VERSION "914 EV telemetry -- generated by generate_914_dbc.py, do not hand-edit"

NS_ :

BS_:

BU_: VCU INVERTER CHARGER LOGGER

BO_ 2667577344 BmsStatus: 8 VCU
 SG_ Flt_CellOverVoltage_Latched : 0|1@1+ (1,0) [0|1] "" LOGGER
 SG_ Flt_CellUnderVoltage_Latched : 1|1@1+ (1,0) [0|1] "" LOGGER
 SG_ Flt_OverTemp_Latched : 2|1@1+ (1,0) [0|1] "" LOGGER
 SG_ Flt_StringImbalance_Latched : 3|1@1+ (1,0) [0|1] "" LOGGER
 SG_ Flt_Pec_Latched : 4|1@1+ (1,0) [0|1] "" LOGGER
 SG_ Flt_CellOverVoltage_Now : 8|1@1+ (1,0) [0|1] "" LOGGER
 SG_ Flt_CellUnderVoltage_Now : 9|1@1+ (1,0) [0|1] "" LOGGER
 SG_ Flt_OverTemp_Now : 10|1@1+ (1,0) [0|1] "" LOGGER
 SG_ Flt_StringImbalance_Now : 11|1@1+ (1,0) [0|1] "" LOGGER
 SG_ Flt_Pec_Now : 12|1@1+ (1,0) [0|1] "" LOGGER
 SG_ Sts_Discharging : 16|1@1+ (1,0) [0|1] "" LOGGER
 SG_ Sts_ChargeSwitch : 17|1@1+ (1,0) [0|1] "" LOGGER
 SG_ Sts_ChargeEnable : 18|1@1+ (1,0) [0|1] "" LOGGER
 SG_ Sts_Contactors : 19|1@1+ (1,0) [0|1] "" LOGGER
 SG_ Sts_Balancing : 20|1@1+ (1,0) [0|1] "" LOGGER
 SG_ Sts_SocReserve : 21|1@1+ (1,0) [0|1] "" LOGGER
 SG_ Sts_VoltageCheckOk : 22|1@1+ (1,0) [0|1] "" LOGGER
 SG_ Sts_StringCheckOk : 23|1@1+ (1,0) [0|1] "" LOGGER
 SG_ Ioexp_G : 24|1@1+ (1,0) [0|1] "" LOGGER
 SG_ Ioexp_LowFuel : 27|1@1+ (1,0) [0|1] "" LOGGER
 SG_ Ioexp_Egr : 28|1@1+ (1,0) [0|1] "" LOGGER
 SG_ Ioexp_BmsErr : 31|1@1+ (1,0) [0|1] "" LOGGER
 SG_ IoexpMask : 32|8@1+ (1,0) [0|255] "" LOGGER
 SG_ ErrCount : 40|16@1+ (1,0) [0|65535] "" LOGGER
 SG_ Gpi_Pin08 : 56|1@1+ (1,0) [0|1] "" LOGGER
 SG_ Gpi_Pin09 : 57|1@1+ (1,0) [0|1] "" LOGGER
 SG_ Gpi_Pin10 : 58|1@1+ (1,0) [0|1] "" LOGGER
 SG_ Gpi_Knob1Sw : 59|1@1+ (1,0) [0|1] "" LOGGER
 SG_ Gpi_Knob2Sw : 60|1@1+ (1,0) [0|1] "" LOGGER
 SG_ Gpi_Pin13 : 61|1@1+ (1,0) [0|1] "" LOGGER
 SG_ Gpi_Pin14 : 62|1@1+ (1,0) [0|1] "" LOGGER
 SG_ Gpi_Pin15 : 63|1@1+ (1,0) [0|1] "" LOGGER

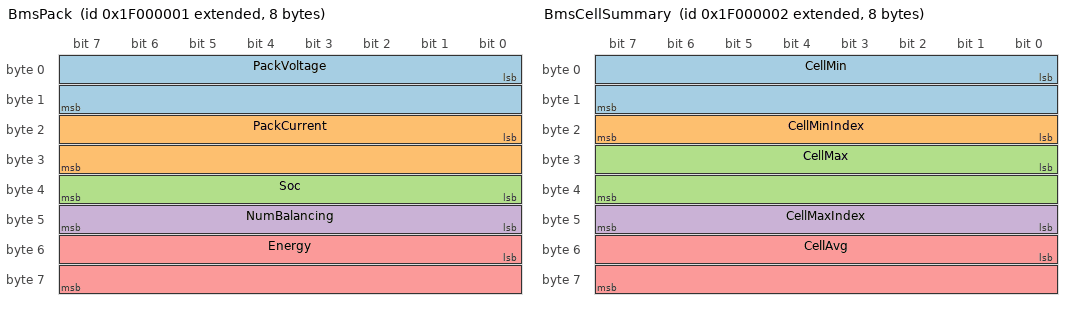
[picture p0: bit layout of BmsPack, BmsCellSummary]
BO_ 2667577345 BmsPack: 8 VCU
 SG_ PackVoltage : 0|16@1+ (0.1,0) [0|6553.5] "V" LOGGER
 SG_ PackCurrent : 16|16@1- (0.01,0) [-327.68|327.67] "A" LOGGER
 SG_ Soc : 32|8@1+ (1,0) [0|100] "%" LOGGER
 SG_ NumBalancing : 40|8@1+ (1,0) [0|168] "" LOGGER
 SG_ Energy : 48|16@1+ (0.01,0) [0|655.35] "kWh" LOGGER

BO_ 2667577346 BmsCellSummary: 8 VCU
 SG_ CellMin : 0|16@1+ (1,0) [0|65535] "mV" LOGGER
 SG_ CellMinIndex : 16|8@1+ (1,0) [0|167] "" LOGGER
 SG_ CellMax : 24|16@1+ (1,0) [0|65535] "mV" LOGGER
 SG_ CellMaxIndex : 40|8@1+ (1,0) [0|167] "" LOGGER
 SG_ CellAvg : 48|16@1+ (1,0) [0|65535] "mV" LOGGER

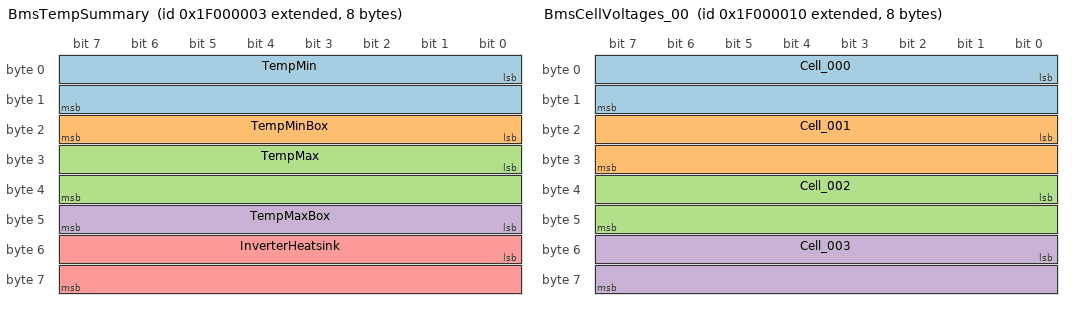
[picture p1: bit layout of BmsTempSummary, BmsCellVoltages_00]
BO_ 2667577347 BmsTempSummary: 8 VCU
 SG_ TempMin : 0|16@1- (0.1,0) [-3276.8|3276.7] "degC" LOGGER
 SG_ TempMinBox : 16|8@1+ (1,0) [0|11] "" LOGGER
 SG_ TempMax : 24|16@1- (0.1,0) [-3276.8|3276.7] "degC" LOGGER
 SG_ TempMaxBox : 40|8@1+ (1,0) [0|11] "" LOGGER
 SG_ InverterHeatsink : 48|16@1- (0.1,0) [-3276.8|3276.7] "degC" LOGGER

BO_ 2667577360 BmsCellVoltages_00: 8 VCU
 SG_ Cell_000 : 0|16@1+ (1,0) [0|65535] "mV" LOGGER
 SG_ Cell_001 : 16|16@1+ (1,0) [0|65535] "mV" LOGGER
 SG_ Cell_002 : 32|16@1+ (1,0) [0|65535] "mV" LOGGER
 SG_ Cell_003 : 48|16@1+ (1,0) [0|65535] "mV" LOGGER

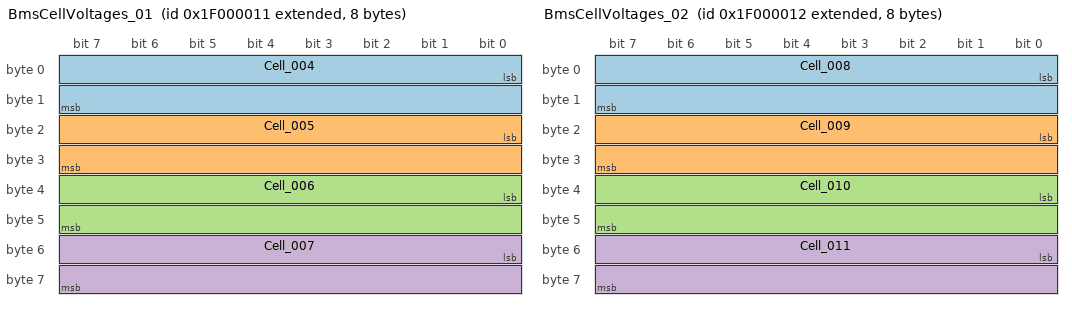
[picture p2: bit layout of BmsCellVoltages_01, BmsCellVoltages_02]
BO_ 2667577361 BmsCellVoltages_01: 8 VCU
 SG_ Cell_004 : 0|16@1+ (1,0) [0|65535] "mV" LOGGER
 SG_ Cell_005 : 16|16@1+ (1,0) [0|65535] "mV" LOGGER
 SG_ Cell_006 : 32|16@1+ (1,0) [0|65535] "mV" LOGGER
 SG_ Cell_007 : 48|16@1+ (1,0) [0|65535] "mV" LOGGER

BO_ 2667577362 BmsCellVoltages_02: 8 VCU
 SG_ Cell_008 : 0|16@1+ (1,0) [0|65535] "mV" LOGGER
 SG_ Cell_009 : 16|16@1+ (1,0) [0|65535] "mV" LOGGER
 SG_ Cell_010 : 32|16@1+ (1,0) [0|65535] "mV" LOGGER
 SG_ Cell_011 : 48|16@1+ (1,0) [0|65535] "mV" LOGGER

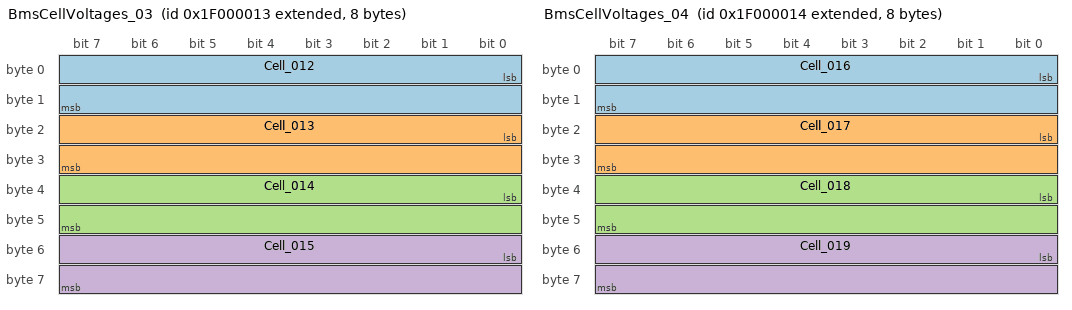
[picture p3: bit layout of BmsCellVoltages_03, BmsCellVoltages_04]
BO_ 2667577363 BmsCellVoltages_03: 8 VCU
 SG_ Cell_012 : 0|16@1+ (1,0) [0|65535] "mV" LOGGER
 SG_ Cell_013 : 16|16@1+ (1,0) [0|65535] "mV" LOGGER
 SG_ Cell_014 : 32|16@1+ (1,0) [0|65535] "mV" LOGGER
 SG_ Cell_015 : 48|16@1+ (1,0) [0|65535] "mV" LOGGER

BO_ 2667577364 BmsCellVoltages_04: 8 VCU
 SG_ Cell_016 : 0|16@1+ (1,0) [0|65535] "mV" LOGGER
 SG_ Cell_017 : 16|16@1+ (1,0) [0|65535] "mV" LOGGER
 SG_ Cell_018 : 32|16@1+ (1,0) [0|65535] "mV" LOGGER
 SG_ Cell_019 : 48|16@1+ (1,0) [0|65535] "mV" LOGGER

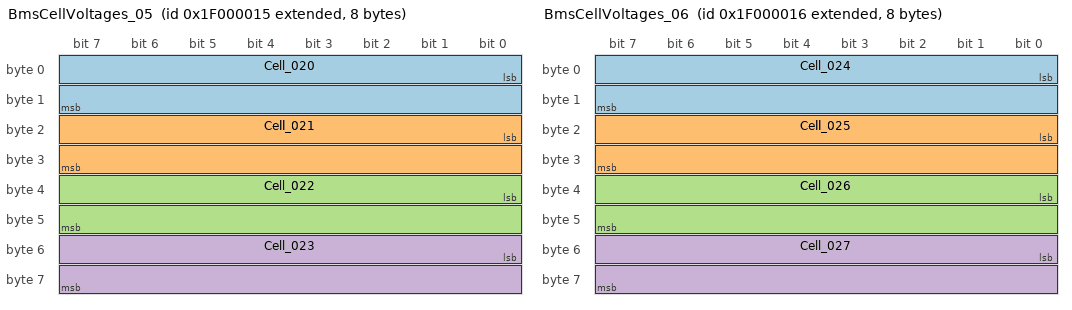
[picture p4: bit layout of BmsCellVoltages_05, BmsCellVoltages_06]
BO_ 2667577365 BmsCellVoltages_05: 8 VCU
 SG_ Cell_020 : 0|16@1+ (1,0) [0|65535] "mV" LOGGER
 SG_ Cell_021 : 16|16@1+ (1,0) [0|65535] "mV" LOGGER
 SG_ Cell_022 : 32|16@1+ (1,0) [0|65535] "mV" LOGGER
 SG_ Cell_023 : 48|16@1+ (1,0) [0|65535] "mV" LOGGER

BO_ 2667577366 BmsCellVoltages_06: 8 VCU
 SG_ Cell_024 : 0|16@1+ (1,0) [0|65535] "mV" LOGGER
 SG_ Cell_025 : 16|16@1+ (1,0) [0|65535] "mV" LOGGER
 SG_ Cell_026 : 32|16@1+ (1,0) [0|65535] "mV" LOGGER
 SG_ Cell_027 : 48|16@1+ (1,0) [0|65535] "mV" LOGGER

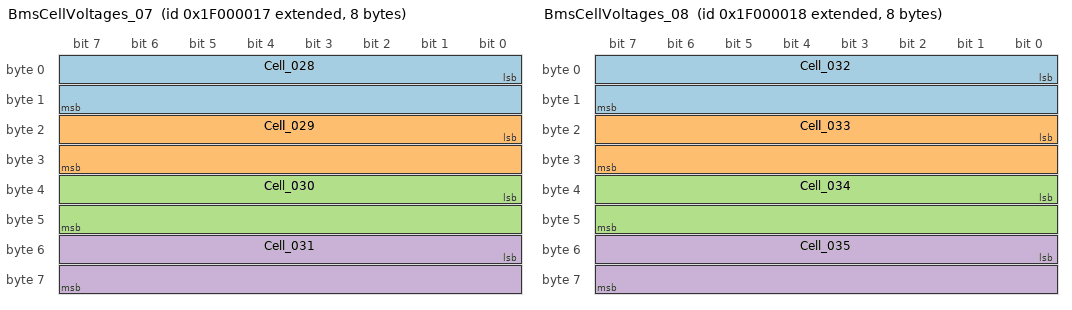
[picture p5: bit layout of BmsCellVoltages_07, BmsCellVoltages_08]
BO_ 2667577367 BmsCellVoltages_07: 8 VCU
 SG_ Cell_028 : 0|16@1+ (1,0) [0|65535] "mV" LOGGER
 SG_ Cell_029 : 16|16@1+ (1,0) [0|65535] "mV" LOGGER
 SG_ Cell_030 : 32|16@1+ (1,0) [0|65535] "mV" LOGGER
 SG_ Cell_031 : 48|16@1+ (1,0) [0|65535] "mV" LOGGER

BO_ 2667577368 BmsCellVoltages_08: 8 VCU
 SG_ Cell_032 : 0|16@1+ (1,0) [0|65535] "mV" LOGGER
 SG_ Cell_033 : 16|16@1+ (1,0) [0|65535] "mV" LOGGER
 SG_ Cell_034 : 32|16@1+ (1,0) [0|65535] "mV" LOGGER
 SG_ Cell_035 : 48|16@1+ (1,0) [0|65535] "mV" LOGGER

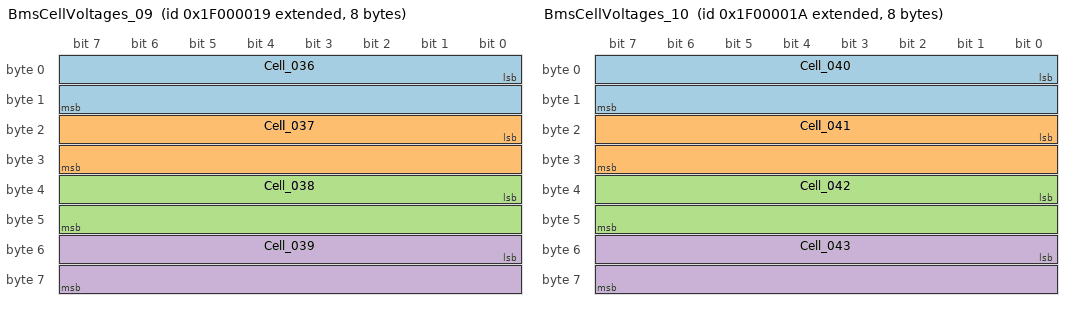
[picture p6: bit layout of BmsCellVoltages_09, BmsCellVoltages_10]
BO_ 2667577369 BmsCellVoltages_09: 8 VCU
 SG_ Cell_036 : 0|16@1+ (1,0) [0|65535] "mV" LOGGER
 SG_ Cell_037 : 16|16@1+ (1,0) [0|65535] "mV" LOGGER
 SG_ Cell_038 : 32|16@1+ (1,0) [0|65535] "mV" LOGGER
 SG_ Cell_039 : 48|16@1+ (1,0) [0|65535] "mV" LOGGER

BO_ 2667577370 BmsCellVoltages_10: 8 VCU
 SG_ Cell_040 : 0|16@1+ (1,0) [0|65535] "mV" LOGGER
 SG_ Cell_041 : 16|16@1+ (1,0) [0|65535] "mV" LOGGER
 SG_ Cell_042 : 32|16@1+ (1,0) [0|65535] "mV" LOGGER
 SG_ Cell_043 : 48|16@1+ (1,0) [0|65535] "mV" LOGGER

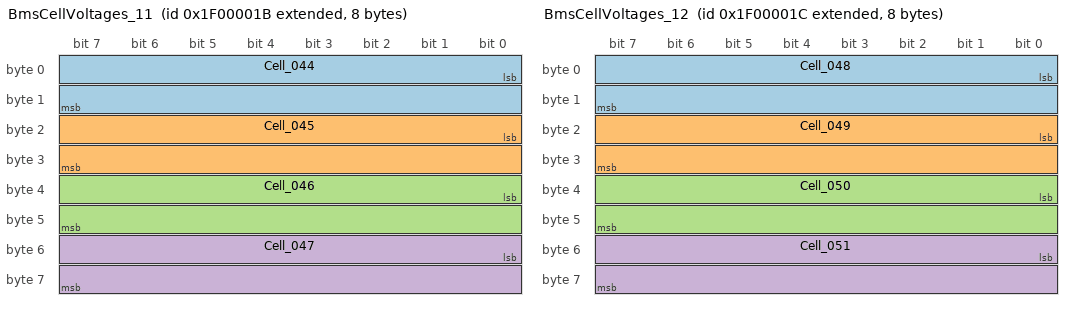
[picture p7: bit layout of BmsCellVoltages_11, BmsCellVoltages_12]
BO_ 2667577371 BmsCellVoltages_11: 8 VCU
 SG_ Cell_044 : 0|16@1+ (1,0) [0|65535] "mV" LOGGER
 SG_ Cell_045 : 16|16@1+ (1,0) [0|65535] "mV" LOGGER
 SG_ Cell_046 : 32|16@1+ (1,0) [0|65535] "mV" LOGGER
 SG_ Cell_047 : 48|16@1+ (1,0) [0|65535] "mV" LOGGER

BO_ 2667577372 BmsCellVoltages_12: 8 VCU
 SG_ Cell_048 : 0|16@1+ (1,0) [0|65535] "mV" LOGGER
 SG_ Cell_049 : 16|16@1+ (1,0) [0|65535] "mV" LOGGER
 SG_ Cell_050 : 32|16@1+ (1,0) [0|65535] "mV" LOGGER
 SG_ Cell_051 : 48|16@1+ (1,0) [0|65535] "mV" LOGGER

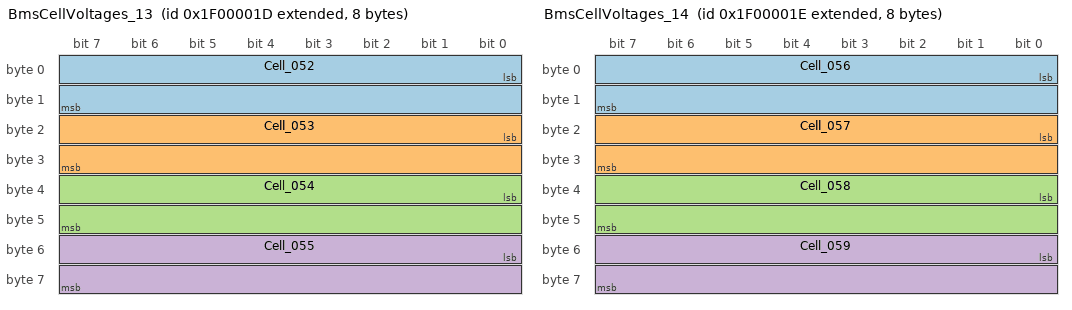
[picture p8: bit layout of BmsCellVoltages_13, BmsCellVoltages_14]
BO_ 2667577373 BmsCellVoltages_13: 8 VCU
 SG_ Cell_052 : 0|16@1+ (1,0) [0|65535] "mV" LOGGER
 SG_ Cell_053 : 16|16@1+ (1,0) [0|65535] "mV" LOGGER
 SG_ Cell_054 : 32|16@1+ (1,0) [0|65535] "mV" LOGGER
 SG_ Cell_055 : 48|16@1+ (1,0) [0|65535] "mV" LOGGER

BO_ 2667577374 BmsCellVoltages_14: 8 VCU
 SG_ Cell_056 : 0|16@1+ (1,0) [0|65535] "mV" LOGGER
 SG_ Cell_057 : 16|16@1+ (1,0) [0|65535] "mV" LOGGER
 SG_ Cell_058 : 32|16@1+ (1,0) [0|65535] "mV" LOGGER
 SG_ Cell_059 : 48|16@1+ (1,0) [0|65535] "mV" LOGGER

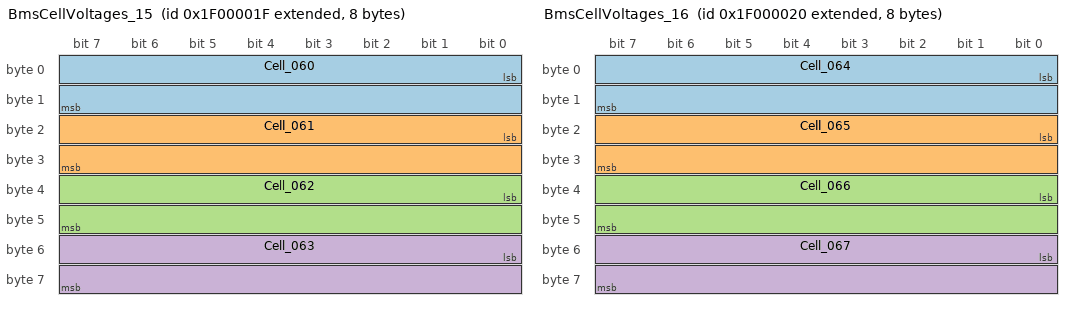
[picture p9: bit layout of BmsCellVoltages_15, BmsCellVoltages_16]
BO_ 2667577375 BmsCellVoltages_15: 8 VCU
 SG_ Cell_060 : 0|16@1+ (1,0) [0|65535] "mV" LOGGER
 SG_ Cell_061 : 16|16@1+ (1,0) [0|65535] "mV" LOGGER
 SG_ Cell_062 : 32|16@1+ (1,0) [0|65535] "mV" LOGGER
 SG_ Cell_063 : 48|16@1+ (1,0) [0|65535] "mV" LOGGER

BO_ 2667577376 BmsCellVoltages_16: 8 VCU
 SG_ Cell_064 : 0|16@1+ (1,0) [0|65535] "mV" LOGGER
 SG_ Cell_065 : 16|16@1+ (1,0) [0|65535] "mV" LOGGER
 SG_ Cell_066 : 32|16@1+ (1,0) [0|65535] "mV" LOGGER
 SG_ Cell_067 : 48|16@1+ (1,0) [0|65535] "mV" LOGGER

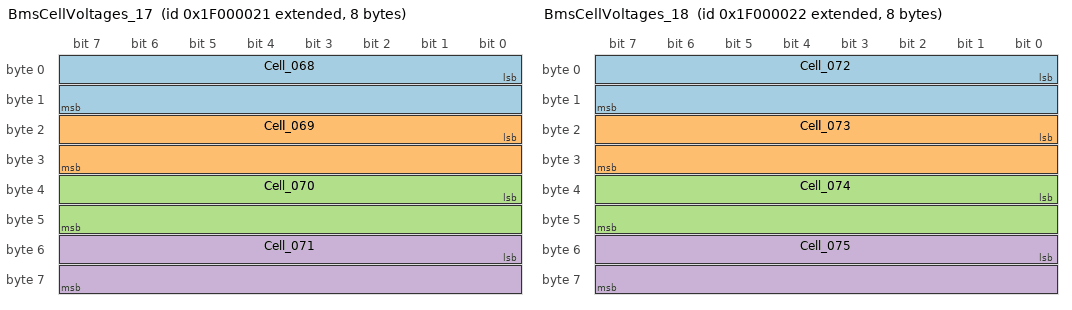
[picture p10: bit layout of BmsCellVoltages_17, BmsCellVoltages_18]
BO_ 2667577377 BmsCellVoltages_17: 8 VCU
 SG_ Cell_068 : 0|16@1+ (1,0) [0|65535] "mV" LOGGER
 SG_ Cell_069 : 16|16@1+ (1,0) [0|65535] "mV" LOGGER
 SG_ Cell_070 : 32|16@1+ (1,0) [0|65535] "mV" LOGGER
 SG_ Cell_071 : 48|16@1+ (1,0) [0|65535] "mV" LOGGER

BO_ 2667577378 BmsCellVoltages_18: 8 VCU
 SG_ Cell_072 : 0|16@1+ (1,0) [0|65535] "mV" LOGGER
 SG_ Cell_073 : 16|16@1+ (1,0) [0|65535] "mV" LOGGER
 SG_ Cell_074 : 32|16@1+ (1,0) [0|65535] "mV" LOGGER
 SG_ Cell_075 : 48|16@1+ (1,0) [0|65535] "mV" LOGGER

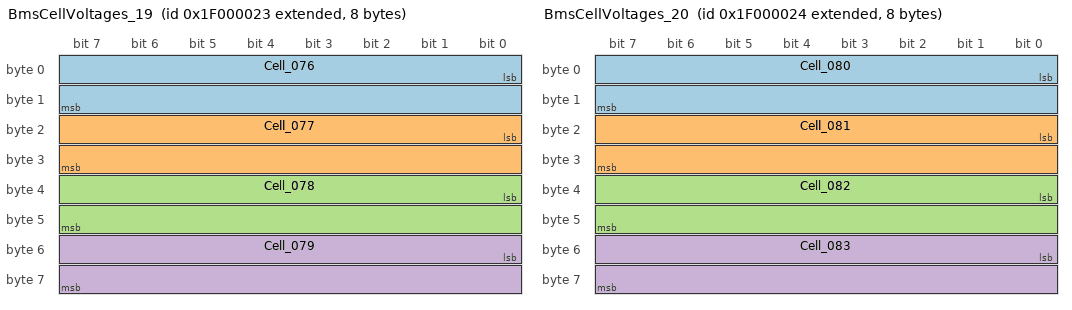
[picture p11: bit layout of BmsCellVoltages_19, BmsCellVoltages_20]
BO_ 2667577379 BmsCellVoltages_19: 8 VCU
 SG_ Cell_076 : 0|16@1+ (1,0) [0|65535] "mV" LOGGER
 SG_ Cell_077 : 16|16@1+ (1,0) [0|65535] "mV" LOGGER
 SG_ Cell_078 : 32|16@1+ (1,0) [0|65535] "mV" LOGGER
 SG_ Cell_079 : 48|16@1+ (1,0) [0|65535] "mV" LOGGER

BO_ 2667577380 BmsCellVoltages_20: 8 VCU
 SG_ Cell_080 : 0|16@1+ (1,0) [0|65535] "mV" LOGGER
 SG_ Cell_081 : 16|16@1+ (1,0) [0|65535] "mV" LOGGER
 SG_ Cell_082 : 32|16@1+ (1,0) [0|65535] "mV" LOGGER
 SG_ Cell_083 : 48|16@1+ (1,0) [0|65535] "mV" LOGGER

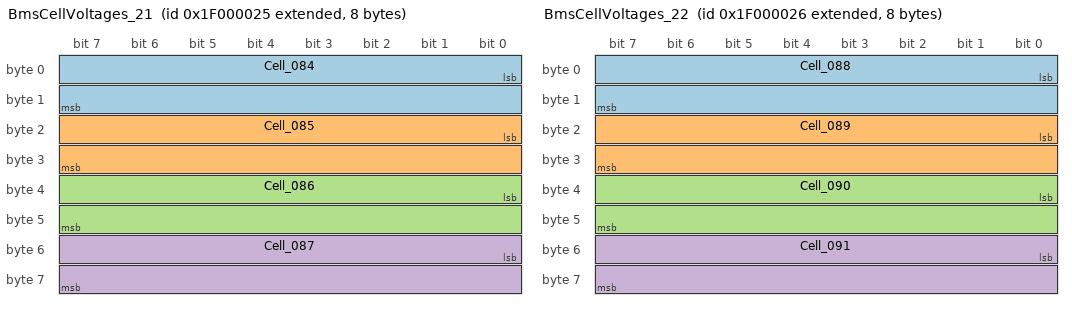
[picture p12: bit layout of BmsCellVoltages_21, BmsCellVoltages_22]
BO_ 2667577381 BmsCellVoltages_21: 8 VCU
 SG_ Cell_084 : 0|16@1+ (1,0) [0|65535] "mV" LOGGER
 SG_ Cell_085 : 16|16@1+ (1,0) [0|65535] "mV" LOGGER
 SG_ Cell_086 : 32|16@1+ (1,0) [0|65535] "mV" LOGGER
 SG_ Cell_087 : 48|16@1+ (1,0) [0|65535] "mV" LOGGER

BO_ 2667577382 BmsCellVoltages_22: 8 VCU
 SG_ Cell_088 : 0|16@1+ (1,0) [0|65535] "mV" LOGGER
 SG_ Cell_089 : 16|16@1+ (1,0) [0|65535] "mV" LOGGER
 SG_ Cell_090 : 32|16@1+ (1,0) [0|65535] "mV" LOGGER
 SG_ Cell_091 : 48|16@1+ (1,0) [0|65535] "mV" LOGGER

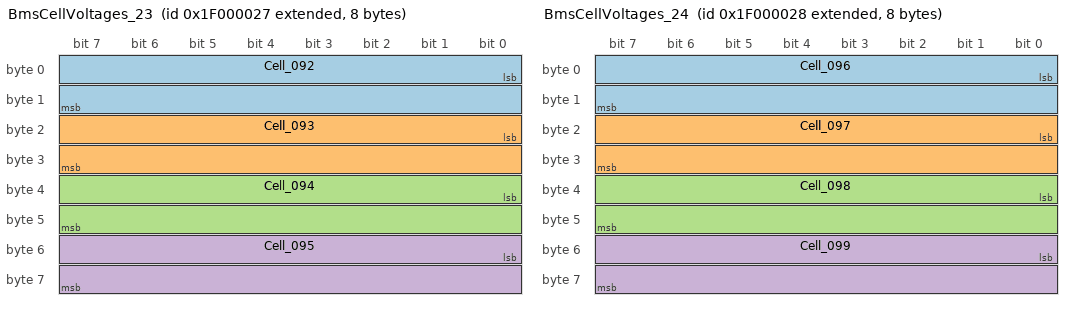
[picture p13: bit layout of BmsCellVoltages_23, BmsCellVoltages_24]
BO_ 2667577383 BmsCellVoltages_23: 8 VCU
 SG_ Cell_092 : 0|16@1+ (1,0) [0|65535] "mV" LOGGER
 SG_ Cell_093 : 16|16@1+ (1,0) [0|65535] "mV" LOGGER
 SG_ Cell_094 : 32|16@1+ (1,0) [0|65535] "mV" LOGGER
 SG_ Cell_095 : 48|16@1+ (1,0) [0|65535] "mV" LOGGER

BO_ 2667577384 BmsCellVoltages_24: 8 VCU
 SG_ Cell_096 : 0|16@1+ (1,0) [0|65535] "mV" LOGGER
 SG_ Cell_097 : 16|16@1+ (1,0) [0|65535] "mV" LOGGER
 SG_ Cell_098 : 32|16@1+ (1,0) [0|65535] "mV" LOGGER
 SG_ Cell_099 : 48|16@1+ (1,0) [0|65535] "mV" LOGGER

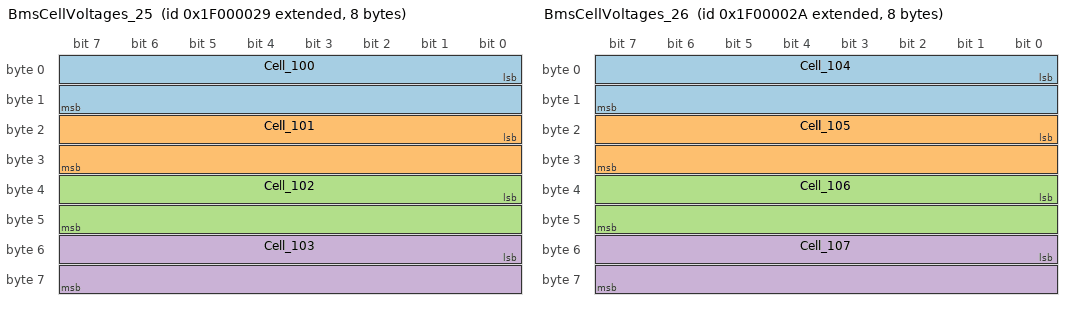
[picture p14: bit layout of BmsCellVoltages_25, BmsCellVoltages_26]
BO_ 2667577385 BmsCellVoltages_25: 8 VCU
 SG_ Cell_100 : 0|16@1+ (1,0) [0|65535] "mV" LOGGER
 SG_ Cell_101 : 16|16@1+ (1,0) [0|65535] "mV" LOGGER
 SG_ Cell_102 : 32|16@1+ (1,0) [0|65535] "mV" LOGGER
 SG_ Cell_103 : 48|16@1+ (1,0) [0|65535] "mV" LOGGER

BO_ 2667577386 BmsCellVoltages_26: 8 VCU
 SG_ Cell_104 : 0|16@1+ (1,0) [0|65535] "mV" LOGGER
 SG_ Cell_105 : 16|16@1+ (1,0) [0|65535] "mV" LOGGER
 SG_ Cell_106 : 32|16@1+ (1,0) [0|65535] "mV" LOGGER
 SG_ Cell_107 : 48|16@1+ (1,0) [0|65535] "mV" LOGGER

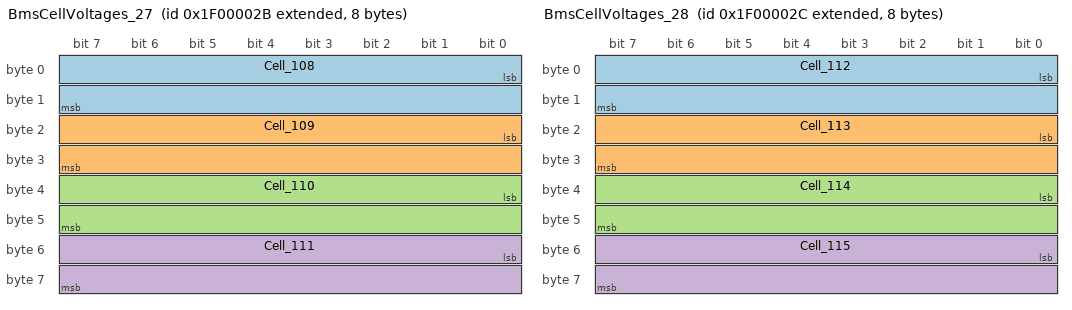
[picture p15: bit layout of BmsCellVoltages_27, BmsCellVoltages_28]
BO_ 2667577387 BmsCellVoltages_27: 8 VCU
 SG_ Cell_108 : 0|16@1+ (1,0) [0|65535] "mV" LOGGER
 SG_ Cell_109 : 16|16@1+ (1,0) [0|65535] "mV" LOGGER
 SG_ Cell_110 : 32|16@1+ (1,0) [0|65535] "mV" LOGGER
 SG_ Cell_111 : 48|16@1+ (1,0) [0|65535] "mV" LOGGER

BO_ 2667577388 BmsCellVoltages_28: 8 VCU
 SG_ Cell_112 : 0|16@1+ (1,0) [0|65535] "mV" LOGGER
 SG_ Cell_113 : 16|16@1+ (1,0) [0|65535] "mV" LOGGER
 SG_ Cell_114 : 32|16@1+ (1,0) [0|65535] "mV" LOGGER
 SG_ Cell_115 : 48|16@1+ (1,0) [0|65535] "mV" LOGGER

BO_ 2667577389 BmsCellVoltages_29: 8 VCU
 SG_ Cell_116 : 0|16@1+ (1,0) [0|65535] "mV" LOGGER
 SG_ Cell_117 : 16|16@1+ (1,0) [0|65535] "mV" LOGGER
 SG_ Cell_118 : 32|16@1+ (1,0) [0|65535] "mV" LOGGER
 SG_ Cell_119 : 48|16@1+ (1,0) [0|65535] "mV" LOGGER

BO_ 2667577390 BmsCellVoltages_30: 8 VCU
 SG_ Cell_120 : 0|16@1+ (1,0) [0|65535] "mV" LOGGER
 SG_ Cell_121 : 16|16@1+ (1,0) [0|65535] "mV" LOGGER
 SG_ Cell_122 : 32|16@1+ (1,0) [0|65535] "mV" LOGGER
 SG_ Cell_123 : 48|16@1+ (1,0) [0|65535] "mV" LOGGER

BO_ 2667577391 BmsCellVoltages_31: 8 VCU
 SG_ Cell_124 : 0|16@1+ (1,0) [0|65535] "mV" LOGGER
 SG_ Cell_125 : 16|16@1+ (1,0) [0|65535] "mV" LOGGER
 SG_ Cell_126 : 32|16@1+ (1,0) [0|65535] "mV" LOGGER
 SG_ Cell_127 : 48|16@1+ (1,0) [0|65535] "mV" LOGGER

BO_ 2667577392 BmsCellVoltages_32: 8 VCU
 SG_ Cell_128 : 0|16@1+ (1,0) [0|65535] "mV" LOGGER
 SG_ Cell_129 : 16|16@1+ (1,0) [0|65535] "mV" LOGGER
 SG_ Cell_130 : 32|16@1+ (1,0) [0|65535] "mV" LOGGER
 SG_ Cell_131 : 48|16@1+ (1,0) [0|65535] "mV" LOGGER

BO_ 2667577393 BmsCellVoltages_33: 8 VCU
 SG_ Cell_132 : 0|16@1+ (1,0) [0|65535] "mV" LOGGER
 SG_ Cell_133 : 16|16@1+ (1,0) [0|65535] "mV" LOGGER
 SG_ Cell_134 : 32|16@1+ (1,0) [0|65535] "mV" LOGGER
 SG_ Cell_135 : 48|16@1+ (1,0) [0|65535] "mV" LOGGER

BO_ 2667577394 BmsCellVoltages_34: 8 VCU
 SG_ Cell_136 : 0|16@1+ (1,0) [0|65535] "mV" LOGGER
 SG_ Cell_137 : 16|16@1+ (1,0) [0|65535] "mV" LOGGER
 SG_ Cell_138 : 32|16@1+ (1,0) [0|65535] "mV" LOGGER
 SG_ Cell_139 : 48|16@1+ (1,0) [0|65535] "mV" LOGGER

BO_ 2667577395 BmsCellVoltages_35: 8 VCU
 SG_ Cell_140 : 0|16@1+ (1,0) [0|65535] "mV" LOGGER
 SG_ Cell_141 : 16|16@1+ (1,0) [0|65535] "mV" LOGGER
 SG_ Cell_142 : 32|16@1+ (1,0) [0|65535] "mV" LOGGER
 SG_ Cell_143 : 48|16@1+ (1,0) [0|65535] "mV" LOGGER

BO_ 2667577396 BmsCellVoltages_36: 8 VCU
 SG_ Cell_144 : 0|16@1+ (1,0) [0|65535] "mV" LOGGER
 SG_ Cell_145 : 16|16@1+ (1,0) [0|65535] "mV" LOGGER
 SG_ Cell_146 : 32|16@1+ (1,0) [0|65535] "mV" LOGGER
 SG_ Cell_147 : 48|16@1+ (1,0) [0|65535] "mV" LOGGER

BO_ 2667577397 BmsCellVoltages_37: 8 VCU
 SG_ Cell_148 : 0|16@1+ (1,0) [0|65535] "mV" LOGGER
 SG_ Cell_149 : 16|16@1+ (1,0) [0|65535] "mV" LOGGER
 SG_ Cell_150 : 32|16@1+ (1,0) [0|65535] "mV" LOGGER
 SG_ Cell_151 : 48|16@1+ (1,0) [0|65535] "mV" LOGGER

BO_ 2667577398 BmsCellVoltages_38: 8 VCU
 SG_ Cell_152 : 0|16@1+ (1,0) [0|65535] "mV" LOGGER
 SG_ Cell_153 : 16|16@1+ (1,0) [0|65535] "mV" LOGGER
 SG_ Cell_154 : 32|16@1+ (1,0) [0|65535] "mV" LOGGER
 SG_ Cell_155 : 48|16@1+ (1,0) [0|65535] "mV" LOGGER

BO_ 2667577399 BmsCellVoltages_39: 8 VCU
 SG_ Cell_156 : 0|16@1+ (1,0) [0|65535] "mV" LOGGER
 SG_ Cell_157 : 16|16@1+ (1,0) [0|65535] "mV" LOGGER
 SG_ Cell_158 : 32|16@1+ (1,0) [0|65535] "mV" LOGGER
 SG_ Cell_159 : 48|16@1+ (1,0) [0|65535] "mV" LOGGER

BO_ 2667577400 BmsCellVoltages_40: 8 VCU
 SG_ Cell_160 : 0|16@1+ (1,0) [0|65535] "mV" LOGGER
 SG_ Cell_161 : 16|16@1+ (1,0) [0|65535] "mV" LOGGER
 SG_ Cell_162 : 32|16@1+ (1,0) [0|65535] "mV" LOGGER
 SG_ Cell_163 : 48|16@1+ (1,0) [0|65535] "mV" LOGGER

BO_ 2667577401 BmsCellVoltages_41: 8 VCU
 SG_ Cell_164 : 0|16@1+ (1,0) [0|65535] "mV" LOGGER
 SG_ Cell_165 : 16|16@1+ (1,0) [0|65535] "mV" LOGGER
 SG_ Cell_166 : 32|16@1+ (1,0) [0|65535] "mV" LOGGER
 SG_ Cell_167 : 48|16@1+ (1,0) [0|65535] "mV" LOGGER

BO_ 2667577408 BmsTemps_0: 8 VCU
 SG_ Temp_00 : 0|16@1- (0.1,0) [-3276.8|3276.7] "degC" LOGGER
 SG_ Temp_01 : 16|16@1- (0.1,0) [-3276.8|3276.7] "degC" LOGGER
 SG_ Temp_02 : 32|16@1- (0.1,0) [-3276.8|3276.7] "degC" LOGGER
 SG_ Temp_03 : 48|16@1- (0.1,0) [-3276.8|3276.7] "degC" LOGGER

BO_ 2667577409 BmsTemps_1: 8 VCU
 SG_ Temp_04 : 0|16@1- (0.1,0) [-3276.8|3276.7] "degC" LOGGER
 SG_ Temp_05 : 16|16@1- (0.1,0) [-3276.8|3276.7] "degC" LOGGER
 SG_ Temp_06 : 32|16@1- (0.1,0) [-3276.8|3276.7] "degC" LOGGER
 SG_ Temp_07 : 48|16@1- (0.1,0) [-3276.8|3276.7] "degC" LOGGER

BO_ 2667577410 BmsTemps_2: 8 VCU
 SG_ Temp_08 : 0|16@1- (0.1,0) [-3276.8|3276.7] "degC" LOGGER
 SG_ Temp_09 : 16|16@1- (0.1,0) [-3276.8|3276.7] "degC" LOGGER
 SG_ Temp_10 : 32|16@1- (0.1,0) [-3276.8|3276.7] "degC" LOGGER
 SG_ Temp_11 : 48|16@1- (0.1,0) [-3276.8|3276.7] "degC" LOGGER

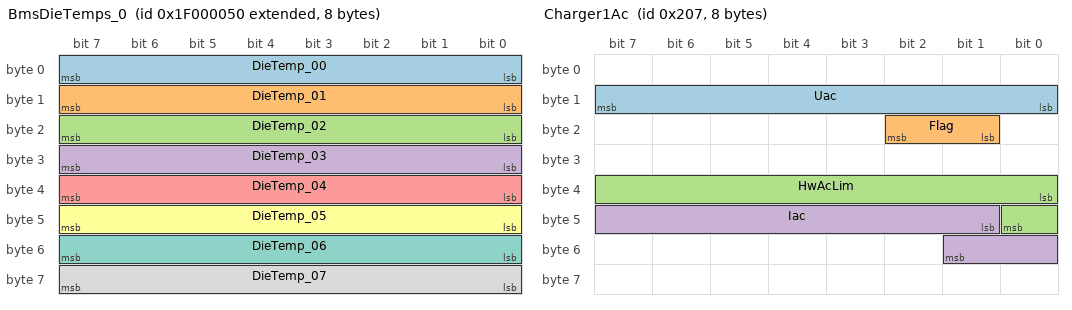
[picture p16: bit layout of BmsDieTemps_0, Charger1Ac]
BO_ 2667577424 BmsDieTemps_0: 8 VCU
 SG_ DieTemp_00 : 0|8@1- (1,0) [-128|127] "degC" LOGGER
 SG_ DieTemp_01 : 8|8@1- (1,0) [-128|127] "degC" LOGGER
 SG_ DieTemp_02 : 16|8@1- (1,0) [-128|127] "degC" LOGGER
 SG_ DieTemp_03 : 24|8@1- (1,0) [-128|127] "degC" LOGGER
 SG_ DieTemp_04 : 32|8@1- (1,0) [-128|127] "degC" LOGGER
 SG_ DieTemp_05 : 40|8@1- (1,0) [-128|127] "degC" LOGGER
 SG_ DieTemp_06 : 48|8@1- (1,0) [-128|127] "degC" LOGGER
 SG_ DieTemp_07 : 56|8@1- (1,0) [-128|127] "degC" LOGGER

BO_ 2667577425 BmsDieTemps_1: 8 VCU
 SG_ DieTemp_08 : 0|8@1- (1,0) [-128|127] "degC" LOGGER
 SG_ DieTemp_09 : 8|8@1- (1,0) [-128|127] "degC" LOGGER
 SG_ DieTemp_10 : 16|8@1- (1,0) [-128|127] "degC" LOGGER
 SG_ DieTemp_11 : 24|8@1- (1,0) [-128|127] "degC" LOGGER

BO_ 2667577440 BmsLinkHealth: 8 VCU
 SG_ CanSwDrops : 0|16@1+ (1,0) [0|65535] "" LOGGER
 SG_ CanHwOverruns : 16|16@1+ (1,0) [0|65535] "" LOGGER
 SG_ CanQueuePeak : 32|16@1+ (1,0) [0|65535] "" LOGGER
 SG_ CanMaxLatency : 48|16@1+ (1,0) [0|65535] "us" LOGGER

BO_ 2667577456 BmsBalanceMask_0: 8 VCU
 SG_ Bal_Cell_000 : 0|1@1+ (1,0) [0|1] "" LOGGER
 SG_ Bal_Cell_001 : 1|1@1+ (1,0) [0|1] "" LOGGER
 SG_ Bal_Cell_002 : 2|1@1+ (1,0) [0|1] "" LOGGER
 SG_ Bal_Cell_003 : 3|1@1+ (1,0) [0|1] "" LOGGER
 SG_ Bal_Cell_004 : 4|1@1+ (1,0) [0|1] "" LOGGER
 SG_ Bal_Cell_005 : 5|1@1+ (1,0) [0|1] "" LOGGER
 SG_ Bal_Cell_006 : 6|1@1+ (1,0) [0|1] "" LOGGER
 SG_ Bal_Cell_007 : 7|1@1+ (1,0) [0|1] "" LOGGER
 SG_ Bal_Cell_008 : 8|1@1+ (1,0) [0|1] "" LOGGER
 SG_ Bal_Cell_009 : 9|1@1+ (1,0) [0|1] "" LOGGER
 SG_ Bal_Cell_010 : 10|1@1+ (1,0) [0|1] "" LOGGER
 SG_ Bal_Cell_011 : 11|1@1+ (1,0) [0|1] "" LOGGER
 SG_ Bal_Cell_012 : 12|1@1+ (1,0) [0|1] "" LOGGER
 SG_ Bal_Cell_013 : 13|1@1+ (1,0) [0|1] "" LOGGER
 SG_ Bal_Cell_014 : 14|1@1+ (1,0) [0|1] "" LOGGER
 SG_ Bal_Cell_015 : 15|1@1+ (1,0) [0|1] "" LOGGER
 SG_ Bal_Cell_016 : 16|1@1+ (1,0) [0|1] "" LOGGER
 SG_ Bal_Cell_017 : 17|1@1+ (1,0) [0|1] "" LOGGER
 SG_ Bal_Cell_018 : 18|1@1+ (1,0) [0|1] "" LOGGER
 SG_ Bal_Cell_019 : 19|1@1+ (1,0) [0|1] "" LOGGER
 SG_ Bal_Cell_020 : 20|1@1+ (1,0) [0|1] "" LOGGER
 SG_ Bal_Cell_021 : 21|1@1+ (1,0) [0|1] "" LOGGER
 SG_ Bal_Cell_022 : 22|1@1+ (1,0) [0|1] "" LOGGER
 SG_ Bal_Cell_023 : 23|1@1+ (1,0) [0|1] "" LOGGER
 SG_ Bal_Cell_024 : 24|1@1+ (1,0) [0|1] "" LOGGER
 SG_ Bal_Cell_025 : 25|1@1+ (1,0) [0|1] "" LOGGER
 SG_ Bal_Cell_026 : 26|1@1+ (1,0) [0|1] "" LOGGER
 SG_ Bal_Cell_027 : 27|1@1+ (1,0) [0|1] "" LOGGER
 SG_ Bal_Cell_028 : 28|1@1+ (1,0) [0|1] "" LOGGER
 SG_ Bal_Cell_029 : 29|1@1+ (1,0) [0|1] "" LOGGER
 SG_ Bal_Cell_030 : 30|1@1+ (1,0) [0|1] "" LOGGER
 SG_ Bal_Cell_031 : 31|1@1+ (1,0) [0|1] "" LOGGER
 SG_ Bal_Cell_032 : 32|1@1+ (1,0) [0|1] "" LOGGER
 SG_ Bal_Cell_033 : 33|1@1+ (1,0) [0|1] "" LOGGER
 SG_ Bal_Cell_034 : 34|1@1+ (1,0) [0|1] "" LOGGER
 SG_ Bal_Cell_035 : 35|1@1+ (1,0) [0|1] "" LOGGER
 SG_ Bal_Cell_036 : 36|1@1+ (1,0) [0|1] "" LOGGER
 SG_ Bal_Cell_037 : 37|1@1+ (1,0) [0|1] "" LOGGER
 SG_ Bal_Cell_038 : 38|1@1+ (1,0) [0|1] "" LOGGER
 SG_ Bal_Cell_039 : 39|1@1+ (1,0) [0|1] "" LOGGER
 SG_ Bal_Cell_040 : 40|1@1+ (1,0) [0|1] "" LOGGER
 SG_ Bal_Cell_041 : 41|1@1+ (1,0) [0|1] "" LOGGER
 SG_ Bal_Cell_042 : 42|1@1+ (1,0) [0|1] "" LOGGER
 SG_ Bal_Cell_043 : 43|1@1+ (1,0) [0|1] "" LOGGER
 SG_ Bal_Cell_044 : 44|1@1+ (1,0) [0|1] "" LOGGER
 SG_ Bal_Cell_045 : 45|1@1+ (1,0) [0|1] "" LOGGER
 SG_ Bal_Cell_046 : 46|1@1+ (1,0) [0|1] "" LOGGER
 SG_ Bal_Cell_047 : 47|1@1+ (1,0) [0|1] "" LOGGER
 SG_ Bal_Cell_048 : 48|1@1+ (1,0) [0|1] "" LOGGER
 SG_ Bal_Cell_049 : 49|1@1+ (1,0) [0|1] "" LOGGER
 SG_ Bal_Cell_050 : 50|1@1+ (1,0) [0|1] "" LOGGER
 SG_ Bal_Cell_051 : 51|1@1+ (1,0) [0|1] "" LOGGER
 SG_ Bal_Cell_052 : 52|1@1+ (1,0) [0|1] "" LOGGER
 SG_ Bal_Cell_053 : 53|1@1+ (1,0) [0|1] "" LOGGER
 SG_ Bal_Cell_054 : 54|1@1+ (1,0) [0|1] "" LOGGER
 SG_ Bal_Cell_055 : 55|1@1+ (1,0) [0|1] "" LOGGER
 SG_ Bal_Cell_056 : 56|1@1+ (1,0) [0|1] "" LOGGER
 SG_ Bal_Cell_057 : 57|1@1+ (1,0) [0|1] "" LOGGER
 SG_ Bal_Cell_058 : 58|1@1+ (1,0) [0|1] "" LOGGER
 SG_ Bal_Cell_059 : 59|1@1+ (1,0) [0|1] "" LOGGER
 SG_ Bal_Cell_060 : 60|1@1+ (1,0) [0|1] "" LOGGER
 SG_ Bal_Cell_061 : 61|1@1+ (1,0) [0|1] "" LOGGER
 SG_ Bal_Cell_062 : 62|1@1+ (1,0) [0|1] "" LOGGER
 SG_ Bal_Cell_063 : 63|1@1+ (1,0) [0|1] "" LOGGER

BO_ 2667577457 BmsBalanceMask_1: 8 VCU
 SG_ Bal_Cell_064 : 0|1@1+ (1,0) [0|1] "" LOGGER
 SG_ Bal_Cell_065 : 1|1@1+ (1,0) [0|1] "" LOGGER
 SG_ Bal_Cell_066 : 2|1@1+ (1,0) [0|1] "" LOGGER
 SG_ Bal_Cell_067 : 3|1@1+ (1,0) [0|1] "" LOGGER
 SG_ Bal_Cell_068 : 4|1@1+ (1,0) [0|1] "" LOGGER
 SG_ Bal_Cell_069 : 5|1@1+ (1,0) [0|1] "" LOGGER
 SG_ Bal_Cell_070 : 6|1@1+ (1,0) [0|1] "" LOGGER
 SG_ Bal_Cell_071 : 7|1@1+ (1,0) [0|1] "" LOGGER
 SG_ Bal_Cell_072 : 8|1@1+ (1,0) [0|1] "" LOGGER
 SG_ Bal_Cell_073 : 9|1@1+ (1,0) [0|1] "" LOGGER
 SG_ Bal_Cell_074 : 10|1@1+ (1,0) [0|1] "" LOGGER
 SG_ Bal_Cell_075 : 11|1@1+ (1,0) [0|1] "" LOGGER
 SG_ Bal_Cell_076 : 12|1@1+ (1,0) [0|1] "" LOGGER
 SG_ Bal_Cell_077 : 13|1@1+ (1,0) [0|1] "" LOGGER
 SG_ Bal_Cell_078 : 14|1@1+ (1,0) [0|1] "" LOGGER
 SG_ Bal_Cell_079 : 15|1@1+ (1,0) [0|1] "" LOGGER
 SG_ Bal_Cell_080 : 16|1@1+ (1,0) [0|1] "" LOGGER
 SG_ Bal_Cell_081 : 17|1@1+ (1,0) [0|1] "" LOGGER
 SG_ Bal_Cell_082 : 18|1@1+ (1,0) [0|1] "" LOGGER
 SG_ Bal_Cell_083 : 19|1@1+ (1,0) [0|1] "" LOGGER
 SG_ Bal_Cell_084 : 20|1@1+ (1,0) [0|1] "" LOGGER
 SG_ Bal_Cell_085 : 21|1@1+ (1,0) [0|1] "" LOGGER
 SG_ Bal_Cell_086 : 22|1@1+ (1,0) [0|1] "" LOGGER
 SG_ Bal_Cell_087 : 23|1@1+ (1,0) [0|1] "" LOGGER
 SG_ Bal_Cell_088 : 24|1@1+ (1,0) [0|1] "" LOGGER
 SG_ Bal_Cell_089 : 25|1@1+ (1,0) [0|1] "" LOGGER
 SG_ Bal_Cell_090 : 26|1@1+ (1,0) [0|1] "" LOGGER
 SG_ Bal_Cell_091 : 27|1@1+ (1,0) [0|1] "" LOGGER
 SG_ Bal_Cell_092 : 28|1@1+ (1,0) [0|1] "" LOGGER
 SG_ Bal_Cell_093 : 29|1@1+ (1,0) [0|1] "" LOGGER
 SG_ Bal_Cell_094 : 30|1@1+ (1,0) [0|1] "" LOGGER
 SG_ Bal_Cell_095 : 31|1@1+ (1,0) [0|1] "" LOGGER
 SG_ Bal_Cell_096 : 32|1@1+ (1,0) [0|1] "" LOGGER
 SG_ Bal_Cell_097 : 33|1@1+ (1,0) [0|1] "" LOGGER
 SG_ Bal_Cell_098 : 34|1@1+ (1,0) [0|1] "" LOGGER
 SG_ Bal_Cell_099 : 35|1@1+ (1,0) [0|1] "" LOGGER
 SG_ Bal_Cell_100 : 36|1@1+ (1,0) [0|1] "" LOGGER
 SG_ Bal_Cell_101 : 37|1@1+ (1,0) [0|1] "" LOGGER
 SG_ Bal_Cell_102 : 38|1@1+ (1,0) [0|1] "" LOGGER
 SG_ Bal_Cell_103 : 39|1@1+ (1,0) [0|1] "" LOGGER
 SG_ Bal_Cell_104 : 40|1@1+ (1,0) [0|1] "" LOGGER
 SG_ Bal_Cell_105 : 41|1@1+ (1,0) [0|1] "" LOGGER
 SG_ Bal_Cell_106 : 42|1@1+ (1,0) [0|1] "" LOGGER
 SG_ Bal_Cell_107 : 43|1@1+ (1,0) [0|1] "" LOGGER
 SG_ Bal_Cell_108 : 44|1@1+ (1,0) [0|1] "" LOGGER
 SG_ Bal_Cell_109 : 45|1@1+ (1,0) [0|1] "" LOGGER
 SG_ Bal_Cell_110 : 46|1@1+ (1,0) [0|1] "" LOGGER
 SG_ Bal_Cell_111 : 47|1@1+ (1,0) [0|1] "" LOGGER
 SG_ Bal_Cell_112 : 48|1@1+ (1,0) [0|1] "" LOGGER
 SG_ Bal_Cell_113 : 49|1@1+ (1,0) [0|1] "" LOGGER
 SG_ Bal_Cell_114 : 50|1@1+ (1,0) [0|1] "" LOGGER
 SG_ Bal_Cell_115 : 51|1@1+ (1,0) [0|1] "" LOGGER
 SG_ Bal_Cell_116 : 52|1@1+ (1,0) [0|1] "" LOGGER
 SG_ Bal_Cell_117 : 53|1@1+ (1,0) [0|1] "" LOGGER
 SG_ Bal_Cell_118 : 54|1@1+ (1,0) [0|1] "" LOGGER
 SG_ Bal_Cell_119 : 55|1@1+ (1,0) [0|1] "" LOGGER
 SG_ Bal_Cell_120 : 56|1@1+ (1,0) [0|1] "" LOGGER
 SG_ Bal_Cell_121 : 57|1@1+ (1,0) [0|1] "" LOGGER
 SG_ Bal_Cell_122 : 58|1@1+ (1,0) [0|1] "" LOGGER
 SG_ Bal_Cell_123 : 59|1@1+ (1,0) [0|1] "" LOGGER
 SG_ Bal_Cell_124 : 60|1@1+ (1,0) [0|1] "" LOGGER
 SG_ Bal_Cell_125 : 61|1@1+ (1,0) [0|1] "" LOGGER
 SG_ Bal_Cell_126 : 62|1@1+ (1,0) [0|1] "" LOGGER
 SG_ Bal_Cell_127 : 63|1@1+ (1,0) [0|1] "" LOGGER

BO_ 2667577458 BmsBalanceMask_2: 8 VCU
 SG_ Bal_Cell_128 : 0|1@1+ (1,0) [0|1] "" LOGGER
 SG_ Bal_Cell_129 : 1|1@1+ (1,0) [0|1] "" LOGGER
 SG_ Bal_Cell_130 : 2|1@1+ (1,0) [0|1] "" LOGGER
 SG_ Bal_Cell_131 : 3|1@1+ (1,0) [0|1] "" LOGGER
 SG_ Bal_Cell_132 : 4|1@1+ (1,0) [0|1] "" LOGGER
 SG_ Bal_Cell_133 : 5|1@1+ (1,0) [0|1] "" LOGGER
 SG_ Bal_Cell_134 : 6|1@1+ (1,0) [0|1] "" LOGGER
 SG_ Bal_Cell_135 : 7|1@1+ (1,0) [0|1] "" LOGGER
 SG_ Bal_Cell_136 : 8|1@1+ (1,0) [0|1] "" LOGGER
 SG_ Bal_Cell_137 : 9|1@1+ (1,0) [0|1] "" LOGGER
 SG_ Bal_Cell_138 : 10|1@1+ (1,0) [0|1] "" LOGGER
 SG_ Bal_Cell_139 : 11|1@1+ (1,0) [0|1] "" LOGGER
 SG_ Bal_Cell_140 : 12|1@1+ (1,0) [0|1] "" LOGGER
 SG_ Bal_Cell_141 : 13|1@1+ (1,0) [0|1] "" LOGGER
 SG_ Bal_Cell_142 : 14|1@1+ (1,0) [0|1] "" LOGGER
 SG_ Bal_Cell_143 : 15|1@1+ (1,0) [0|1] "" LOGGER
 SG_ Bal_Cell_144 : 16|1@1+ (1,0) [0|1] "" LOGGER
 SG_ Bal_Cell_145 : 17|1@1+ (1,0) [0|1] "" LOGGER
 SG_ Bal_Cell_146 : 18|1@1+ (1,0) [0|1] "" LOGGER
 SG_ Bal_Cell_147 : 19|1@1+ (1,0) [0|1] "" LOGGER
 SG_ Bal_Cell_148 : 20|1@1+ (1,0) [0|1] "" LOGGER
 SG_ Bal_Cell_149 : 21|1@1+ (1,0) [0|1] "" LOGGER
 SG_ Bal_Cell_150 : 22|1@1+ (1,0) [0|1] "" LOGGER
 SG_ Bal_Cell_151 : 23|1@1+ (1,0) [0|1] "" LOGGER
 SG_ Bal_Cell_152 : 24|1@1+ (1,0) [0|1] "" LOGGER
 SG_ Bal_Cell_153 : 25|1@1+ (1,0) [0|1] "" LOGGER
 SG_ Bal_Cell_154 : 26|1@1+ (1,0) [0|1] "" LOGGER
 SG_ Bal_Cell_155 : 27|1@1+ (1,0) [0|1] "" LOGGER
 SG_ Bal_Cell_156 : 28|1@1+ (1,0) [0|1] "" LOGGER
 SG_ Bal_Cell_157 : 29|1@1+ (1,0) [0|1] "" LOGGER
 SG_ Bal_Cell_158 : 30|1@1+ (1,0) [0|1] "" LOGGER
 SG_ Bal_Cell_159 : 31|1@1+ (1,0) [0|1] "" LOGGER
 SG_ Bal_Cell_160 : 32|1@1+ (1,0) [0|1] "" LOGGER
 SG_ Bal_Cell_161 : 33|1@1+ (1,0) [0|1] "" LOGGER
 SG_ Bal_Cell_162 : 34|1@1+ (1,0) [0|1] "" LOGGER
 SG_ Bal_Cell_163 : 35|1@1+ (1,0) [0|1] "" LOGGER
 SG_ Bal_Cell_164 : 36|1@1+ (1,0) [0|1] "" LOGGER
 SG_ Bal_Cell_165 : 37|1@1+ (1,0) [0|1] "" LOGGER
 SG_ Bal_Cell_166 : 38|1@1+ (1,0) [0|1] "" LOGGER
 SG_ Bal_Cell_167 : 39|1@1+ (1,0) [0|1] "" LOGGER

BO_ 2667577584 BmsDiagnostic: 8 VCU
 SG_ DiagCode : 0|8@1+ (1,0) [0|255] "" LOGGER
 SG_ DiagArg1 : 8|16@1+ (1,0) [0|65535] "" LOGGER
 SG_ DiagArg2 : 24|16@1+ (1,0) [0|65535] "" LOGGER
 SG_ DiagArg3 : 40|16@1+ (1,0) [0|65535] "" LOGGER

BO_ 2684354558 SchemaId: 8 VCU
 SG_ SchemaMajor : 0|8@1+ (1,0) [0|255] "" LOGGER
 SG_ SchemaMinor : 8|8@1+ (1,0) [0|255] "" LOGGER
 SG_ SchemaHash : 16|32@1+ (1,0) [0|4294967295] "" LOGGER

BO_ 2684354559 SlcanIntegrity: 8 VCU
 SG_ SeqCounter : 0|16@1+ (1,0) [0|65535] "" LOGGER
 SG_ FrameCount : 16|16@1+ (1,0) [0|65535] "" LOGGER
 SG_ Crc16 : 32|16@1+ (1,0) [0|65535] "" LOGGER

BO_ 1 InverterStatus: 8 INVERTER
 SG_ InvDcVoltage : 0|16@1+ (0.1,0) [0|6553.5] "V" LOGGER
 SG_ InvHeatsinkTemp : 16|16@1- (0.1,0) [-3276.8|3276.7] "degC" LOGGER
 SG_ InvRpm : 32|16@1+ (1,0) [0|65535] "rpm" LOGGER

BO_ 2 InverterState: 8 INVERTER
 SG_ InvSts_UdcLow : 0|1@1+ (1,0) [0|1] "" LOGGER
 SG_ InvSts_UdcHigh : 1|1@1+ (1,0) [0|1] "" LOGGER
 SG_ InvSts_UdcBelowUdcSw : 2|1@1+ (1,0) [0|1] "" LOGGER
 SG_ InvSts_UdcLim : 3|1@1+ (1,0) [0|1] "" LOGGER
 SG_ InvSts_EmcyStop : 4|1@1+ (1,0) [0|1] "" LOGGER
 SG_ InvSts_MProt : 5|1@1+ (1,0) [0|1] "" LOGGER
 SG_ InvSts_PotPressed : 6|1@1+ (1,0) [0|1] "" LOGGER
 SG_ InvSts_TmpHs : 7|1@1+ (1,0) [0|1] "" LOGGER
 SG_ InvSts_WaitStart : 8|1@1+ (1,0) [0|1] "" LOGGER
 SG_ InvSts_BrakeCheck : 9|1@1+ (1,0) [0|1] "" LOGGER
 SG_ InvOpmode : 16|8@1+ (1,0) [0|6] "" LOGGER
 SG_ InvIo_Cruise : 24|1@1+ (1,0) [0|1] "" LOGGER
 SG_ InvIo_Start : 25|1@1+ (1,0) [0|1] "" LOGGER
 SG_ InvIo_Brake : 26|1@1+ (1,0) [0|1] "" LOGGER
 SG_ InvIo_Fwd : 27|1@1+ (1,0) [0|1] "" LOGGER
 SG_ InvIo_Rev : 28|1@1+ (1,0) [0|1] "" LOGGER
 SG_ InvIo_Bms : 29|1@1+ (1,0) [0|1] "" LOGGER
 SG_ InvAuxVoltage : 32|8@1+ (0.1,0) [0|25.5] "V" LOGGER
 SG_ InvIo_Ocur : 40|2@1+ (1,0) [0|2] "" LOGGER
 SG_ InvIo_Desat : 42|2@1+ (1,0) [0|2] "" LOGGER
 SG_ InvIo_MProt : 44|1@1+ (1,0) [0|1] "" LOGGER
 SG_ InvIo_EmcyStop : 45|1@1+ (1,0) [0|1] "" LOGGER

BO_ 3 InverterFoc: 8 INVERTER
 SG_ InvId : 0|16@1- (0.1,0) [-3276.8|3276.7] "A" LOGGER
 SG_ InvIq : 16|16@1- (-0.1,0) [-3276.8|3276.7] "A" LOGGER
 SG_ InvIfw : 32|16@1- (0.1,0) [-3276.8|3276.7] "A" LOGGER
 SG_ InvAmp : 48|16@1+ (1,0) [0|65535] "dig" LOGGER

BO_ 4 InverterThrottle: 8 INVERTER
 SG_ InvPotNom : 32|8@1- (1,0) [-100|100] "%" LOGGER
 SG_ InvCpuLoad : 56|8@1+ (1,0) [0|100] "%" LOGGER

BO_ 63 VcuControl: 8 VCU
 SG_ BmsLimit : 29|1@1+ (1,0) [0|1] "" LOGGER

BO_ 1537 InverterSdoReq: 8 VCU
 SG_ SdoCmd : 0|8@1+ (1,0) [0|255] "" INVERTER
 SG_ SdoIndex : 8|16@1+ (1,0) [0|65535] "" INVERTER
 SG_ SdoSubIndex : 24|8@1+ (1,0) [0|255] "" INVERTER
 SG_ SdoData : 32|32@1- (1,0) [-2147483648|2147483647] "" INVERTER

BO_ 1409 InverterSdoResp: 8 INVERTER
 SG_ SdoCmd : 0|8@1+ (1,0) [0|255] "" LOGGER
 SG_ SdoIndex : 8|16@1+ (1,0) [0|65535] "" LOGGER
 SG_ SdoSubIndex : 24|8@1+ (1,0) [0|255] "" LOGGER
 SG_ SdoData : 32|32@1- (1,0) [-2147483648|2147483647] "" LOGGER

BO_ 519 Charger1Ac: 8 CHARGER
 SG_ Uac : 8|8@1+ (1,0) [0|255] "V" LOGGER
 SG_ Flag : 17|2@1+ (1,0) [0|3] "" LOGGER
 SG_ HwAcLim : 32|9@1+ (0.06666666666666667,0) [0|34.1] "A" LOGGER
 SG_ Iac : 41|9@1+ (0.06666666666666667,0) [0|34.1] "A" LOGGER

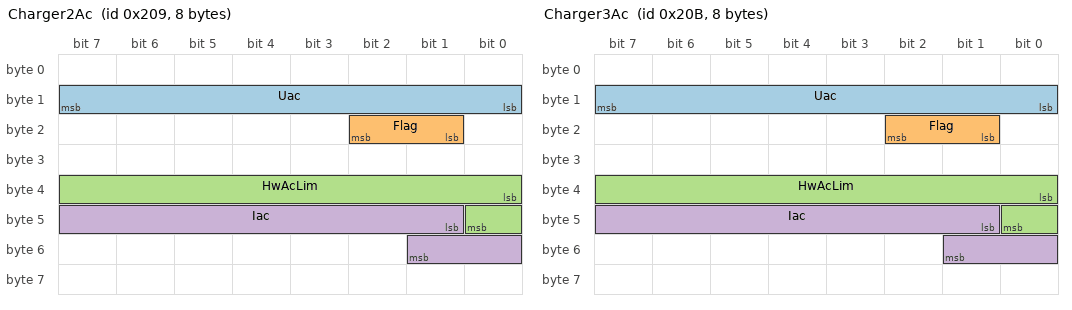
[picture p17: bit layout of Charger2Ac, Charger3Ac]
BO_ 521 Charger2Ac: 8 CHARGER
 SG_ Uac : 8|8@1+ (1,0) [0|255] "V" LOGGER
 SG_ Flag : 17|2@1+ (1,0) [0|3] "" LOGGER
 SG_ HwAcLim : 32|9@1+ (0.06666666666666667,0) [0|34.1] "A" LOGGER
 SG_ Iac : 41|9@1+ (0.06666666666666667,0) [0|34.1] "A" LOGGER

BO_ 523 Charger3Ac: 8 CHARGER
 SG_ Uac : 8|8@1+ (1,0) [0|255] "V" LOGGER
 SG_ Flag : 17|2@1+ (1,0) [0|3] "" LOGGER
 SG_ HwAcLim : 32|9@1+ (0.06666666666666667,0) [0|34.1] "A" LOGGER
 SG_ Iac : 41|9@1+ (0.06666666666666667,0) [0|34.1] "A" LOGGER

BO_ 535 Charger1Status: 8 CHARGER
 SG_ Stt : 0|8@1+ (1,0) [0|255] "" LOGGER

BO_ 537 Charger2Status: 8 CHARGER
 SG_ Stt : 0|8@1+ (1,0) [0|255] "" LOGGER

BO_ 539 Charger3Status: 8 CHARGER
 SG_ Stt : 0|8@1+ (1,0) [0|255] "" LOGGER

BO_ 551 Charger1Dc: 8 CHARGER
 SG_ Udc : 16|16@1+ (0.01052856,0) [0|690.09] "V" LOGGER
 SG_ Idc : 32|16@1+ (0.000839233,0) [0|55.0] "A" LOGGER

BO_ 553 Charger2Dc: 8 CHARGER
 SG_ Udc : 16|16@1+ (0.01052856,0) [0|690.09] "V" LOGGER
 SG_ Idc : 32|16@1+ (0.000839233,0) [0|55.0] "A" LOGGER

BO_ 555 Charger3Dc: 8 CHARGER
 SG_ Udc : 16|16@1+ (0.01052856,0) [0|690.09] "V" LOGGER
 SG_ Idc : 32|16@1+ (0.000839233,0) [0|55.0] "A" LOGGER

BO_ 567 Charger1Temps: 8 CHARGER
 SG_ Tmp1 : 0|8@1+ (1,-40) [-40|215] "degC" LOGGER
 SG_ Tmp2 : 8|8@1+ (1,-40) [-40|215] "degC" LOGGER
 SG_ TmpIn : 40|8@1+ (1,-40) [-40|215] "degC" LOGGER

BO_ 569 Charger2Temps: 8 CHARGER
 SG_ Tmp1 : 0|8@1+ (1,-40) [-40|215] "degC" LOGGER
 SG_ Tmp2 : 8|8@1+ (1,-40) [-40|215] "degC" LOGGER
 SG_ TmpIn : 40|8@1+ (1,-40) [-40|215] "degC" LOGGER

BO_ 571 Charger3Temps: 8 CHARGER
 SG_ Tmp1 : 0|8@1+ (1,-40) [-40|215] "degC" LOGGER
 SG_ Tmp2 : 8|8@1+ (1,-40) [-40|215] "degC" LOGGER
 SG_ TmpIn : 40|8@1+ (1,-40) [-40|215] "degC" LOGGER

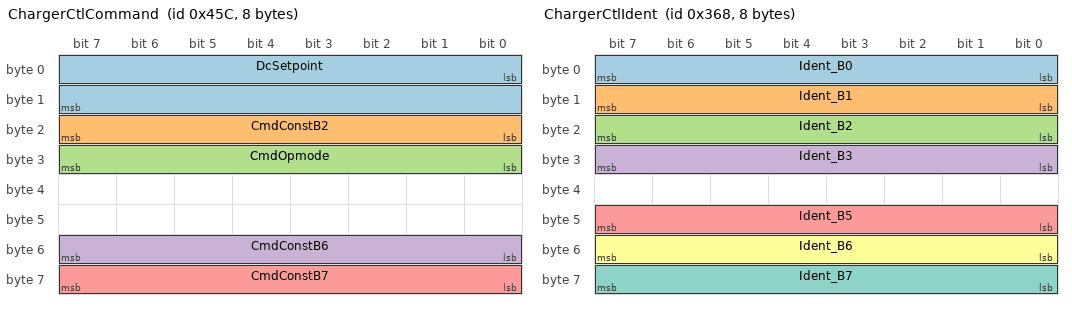
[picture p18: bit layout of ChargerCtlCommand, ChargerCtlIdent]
BO_ 1116 ChargerCtlCommand: 8 CHARGER
 SG_ DcSetpoint : 0|16@1+ (0.01,0) [0|655.35] "V" LOGGER
 SG_ CmdConstB2 : 16|8@1+ (1,0) [0|255] "" LOGGER
 SG_ CmdOpmode : 24|8@1+ (0.03125,-0.4375) [0|7] "" LOGGER
 SG_ CmdConstB6 : 48|8@1+ (1,0) [0|255] "" LOGGER
 SG_ CmdConstB7 : 56|8@1+ (1,0) [0|255] "" LOGGER

BO_ 1068 ChargerCtlModule1: 8 CHARGER
 SG_ ModConstB0 : 0|8@1+ (1,0) [0|255] "" LOGGER
 SG_ ModAcVoltagePlaceholder : 8|8@1+ (1,0) [0|255] "" LOGGER
 SG_ ModAcLimit : 16|16@1+ (0.0006666667,-0.0) [0|43.69] "A" LOGGER
 SG_ ModOpmode : 32|8@1+ (0.0064935065,-0.6493506494) [0|1] "" LOGGER

BO_ 1084 ChargerCtlModule2: 8 CHARGER
 SG_ ModConstB0 : 0|8@1+ (1,0) [0|255] "" LOGGER
 SG_ ModAcVoltagePlaceholder : 8|8@1+ (1,0) [0|255] "" LOGGER
 SG_ ModAcLimit : 16|16@1+ (0.0006666667,-0.0) [0|43.69] "A" LOGGER
 SG_ ModOpmode : 32|8@1+ (0.0064935065,-0.6493506494) [0|1] "" LOGGER

BO_ 1100 ChargerCtlModule3: 8 CHARGER
 SG_ ModConstB0 : 0|8@1+ (1,0) [0|255] "" LOGGER
 SG_ ModAcVoltagePlaceholder : 8|8@1+ (1,0) [0|255] "" LOGGER
 SG_ ModAcLimit : 16|16@1+ (0.0006666667,-0.0) [0|43.69] "A" LOGGER
 SG_ ModOpmode : 32|8@1+ (0.0064935065,-0.6493506494) [0|1] "" LOGGER

BO_ 872 ChargerCtlIdent: 8 CHARGER
 SG_ Ident_B0 : 0|8@1+ (1,0) [0|255] "" LOGGER
 SG_ Ident_B1 : 8|8@1+ (1,0) [0|255] "" LOGGER
 SG_ Ident_B2 : 16|8@1+ (1,0) [0|255] "" LOGGER
 SG_ Ident_B3 : 24|8@1+ (1,0) [0|255] "" LOGGER
 SG_ Ident_B5 : 40|8@1+ (1,0) [0|255] "" LOGGER
 SG_ Ident_B6 : 48|8@1+ (1,0) [0|255] "" LOGGER
 SG_ Ident_B7 : 56|8@1+ (1,0) [0|255] "" LOGGER

BO_ 264 ChargerCtlChademoLimits: 8 CHARGER
 SG_ ChademoMaxVoltage : 8|16@1+ (1,0) [0|65535] "V" LOGGER
 SG_ ChademoCurrentLimit : 24|8@1+ (1,0) [0|255] "A" LOGGER

BO_ 265 ChargerCtlChademoStatus: 8 CHARGER
 SG_ ChademoUdc : 8|16@1+ (1,0) [0|65535] "V" LOGGER
 SG_ ChademoIdc : 24|16@1+ (1,0) [0|65535] "A" LOGGER
 SG_ ChademoOpmode : 40|3@1+ (0.2,-0.0) [0|1] "" LOGGER

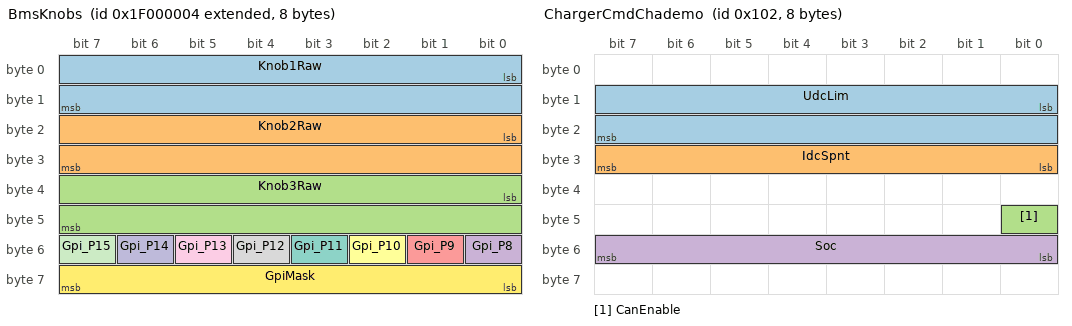
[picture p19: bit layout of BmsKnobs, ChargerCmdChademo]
BO_ 2667577348 BmsKnobs: 8 VCU
 SG_ Knob1Raw : 0|16@1+ (1,0) [0|65535] "" LOGGER
 SG_ Knob2Raw : 16|16@1+ (1,0) [0|65535] "" LOGGER
 SG_ Knob3Raw : 32|16@1+ (1,0) [0|65535] "" LOGGER
 SG_ Gpi_P8 : 48|1@1+ (1,0) [0|1] "" LOGGER
 SG_ Gpi_P9 : 49|1@1+ (1,0) [0|1] "" LOGGER
 SG_ Gpi_P10 : 50|1@1+ (1,0) [0|1] "" LOGGER
 SG_ Gpi_P11 : 51|1@1+ (1,0) [0|1] "" LOGGER
 SG_ Gpi_P12 : 52|1@1+ (1,0) [0|1] "" LOGGER
 SG_ Gpi_P13 : 53|1@1+ (1,0) [0|1] "" LOGGER
 SG_ Gpi_P14 : 54|1@1+ (1,0) [0|1] "" LOGGER
 SG_ Gpi_P15 : 55|1@1+ (1,0) [0|1] "" LOGGER
 SG_ GpiMask : 56|8@1+ (1,0) [0|255] "" LOGGER

BO_ 258 ChargerCmdChademo: 8 VCU
 SG_ UdcLim : 8|16@1+ (1,0) [0|420] "V" LOGGER
 SG_ IdcSpnt : 24|8@1+ (1,0) [0|45] "A" LOGGER
 SG_ CanEnable : 40|1@1+ (1,0) [0|1] "" LOGGER
 SG_ Soc : 48|8@1+ (1,0) [0|100] "%" LOGGER

BO_ 259 ChargerCmdSetpoint: 8 VCU
 SG_ UdcSpnt : 0|16@1+ (1,0) [0|420] "V" LOGGER
 SG_ ChargerEna : 16|8@1+ (1,0) [0|7] "" LOGGER
 SG_ ChargerAuto : 24|8@1+ (1,0) [0|1] "" LOGGER

CM_ BO_ 2667577344 "BMS status and faults, one per cell-sense scan (10 Hz, 2 Hz charging). Latched and instantaneous fault bits are both present on purpose: the dash lamp follows the instantaneous state while the inverter's 50 percent throttle limit follows the latched one, so a single-cycle sag half-throttles the car with only a lamp flicker. Logging both makes that divergence visible.";
CM_ SG_ 2667577344 IoexpMask "MCP_BMS_THREAD_MASK. Bits outside this mask are not owned by the BMS thread and the Ioexp_ signals say nothing about them.";
CM_ SG_ 2667577344 Ioexp_G "Mirror of the literal byte passed to MCP23017::write_mask(), so the log records what the dash was told rather than a reconstruction of it.";
CM_ SG_ 2667577344 Gpi_Knob1Sw "MCP23017 port B input bits, pin 8+n in bit n. RESERVED: the mainline firmware does not read the input side at all. Only the charge-control branch does, via ioexp->read_mask(MCP_BMS_THREAD_READ_MASK) for the CC/CV knob switches on pins 11 and 12. Held in the map so that branch can land without renumbering this frame. Transmit 0 until then, and note that 0 is indistinguishable from 'switches open' -- use the firmware version to tell 'not implemented' from 'nothing pressed'.";
CM_ BO_ 2667577346 "CellAvg is packVoltage / 84, the same expression the live display uses at BmsThread.cpp:920. Note 84, cells in series, NOT 168 total cells -- the two strings are in parallel. The commented-out display block just above divides by 168 and would read half the true value.";
CM_ SG_ 2667577346 CellMinIndex "Flat cell index 0..167, identical to the indexing of Cell_000..Cell_167 and of the balancing mask. Display label is 'A'+index/28 and index%28+1; that geometry is deliberately not encoded on the wire because the pack layout has changed before.";
CM_ BO_ 2667577424 "Die temperatures are whole degrees because the source is a uint8: raw*0.0001/0.0076 - 276. Encoding them at 0.1 degC would invent precision.";
CM_ BO_ 2667577456 "One bit per cell, indexed identically to Cell_000..Cell_167. Commanded discharge state, not current flow -- discharge is muted around the measurement. popcount over all three frames must equal NumBalancing on the same scan.";
CM_ BO_ 2684354558 "Identifies the schema this stream was produced with, broadcast at 1 Hz so a consumer joining mid-stream attributes at most one second of data to an unknown schema. SchemaHash is a digest of the map's structure -- message ids, signal names, start bits, lengths, signedness and scaling -- and deliberately excludes comments, units and value tables, so rewording documentation does not invalidate every consumer's cache. Generated into a C header by generate_914_dbc.py so the broadcast value cannot drift from the DBC. Consumer rules: hash equal, proceed; hash differs but major equal, additive change, keep decoding known signals and log once; major differs, stop and quarantine, because decoding with the wrong major yields plausible wrong numbers rather than an error.";
CM_ BO_ 2684354559 "Not part of SLCAN. Counter gaps expose lost frames and the CRC16 over every byte since the previous integrity frame exposes substitutions that the frame's own length check misses. Other tools can ignore this id.";
CM_ SG_ 1 InvDcVoltage "HV DC bus voltage. Scale is 0.1 V because the inverter's CAN map sends udc at gain 10 -- defined by that map entry, not inferred from a capture. Before 2026-08-10 nothing was mapped here at all and these bytes read zero.";
CM_ BO_ 63 "Transmitted by the VCU, so the proxy never receives it -- a CAN node does not see its own frames. It must be echoed into the log deliberately at transmit request, which is evidence of intent rather than proof of arbitration success. Only BmsLimit is verified; the rest of the layout is not yet mapped.";
CM_ BO_ 1537 "SDO read request from the VCU to the inverter, 0x600 + nodeid. The VCU polls pot (id 2015), pot2 (2016) and regenpreset (2051) round-robin, one outstanding at a time, at 10 Hz while opmode is not Off and 1 Hz otherwise. Parameters are named by unique ID -- index 0x2100 | (id >> 8), subIndex id & 0xFF -- and NOT by array position under index 0x2000, because positions shift between firmware builds. Transmitted by the VCU, so like 0x03F it is echoed into the log at transmit request rather than received. A request with no matching reply before the next poll is a dropped sample; it is visible in the log as a 0x601 with no 0x581 after it, which is why no separate loss counter exists. Strictly a diagnostic path: SDO has no sequence counter, no CRC and no timeout semantics, so nothing in the control loop may depend on it.";
CM_ BO_ 1409 "SDO reply from the inverter, 0x580 + nodeid. The requested index and subIndex are echoed, so a request and its reply pair exactly even if the reply is late. SdoCmd 0x43 is a successful read; 0x80 is an abort, and then SdoData is the abort code rather than a value -- 0x06020000 means the index is wrong for this firmware build, which retrying cannot fix. For a parameter read SdoData is s32fp: divide by 32, signed.";
CM_ BO_ 2667577348 "Dash knob bring-up. Knob1Raw/Knob2Raw/Knob3Raw are AnalogIn::read_u16() on p15, p16 and p20 -- the only three analog pins free on this board, since p17-p19 are the charge, brake and reverse inputs. Which physical knob sits on which channel is what the capture is for, so do not assume the numbering means anything yet.";
CM_ SG_ 519 Iac "9 bits at bit 41, spanning byte 5 bits 1-7 and byte 6 bits 0-1. Main.cpp used to read 15 bits here (data[5]>>1 plus data[6]<<7), taking six bits above the field that the charger maps to nothing; fixed 2026-08-22 to mask byte 6 to two bits.";
CM_ SG_ 519 Flag "Module status bits: 1 Enabled, 2 Fault. Two bits is the full wire field. The charger's third flag value, 4=CheckAlive, is one it sets on itself and expects this frame to clear by overwriting -- a module that goes quiet leaves it set, which is how the charger detects a dead module. It is never transmitted.";
CM_ SG_ 519 HwAcLim "Hardware AC current limit reported by the module. All three modules send their own and the charger maps every one onto a single hwaclim parameter, so on the charger side the last frame received wins.";
CM_ BO_ 551 "Module DC output, measured at the module rather than at the pack. The charger sums Idc across the three for its idc, and takes the highest Udc of the three as its udc -- which is the value CheckVoltage() compares against udclim to terminate a charge.";
CM_ BO_ 567 "Module temperatures, offset -40 degC. Tmp1 and Tmp2 are module-internal, TmpIn is the inlet. Which of the three track real conditions has not been checked against a logged session yet.";
CM_ BO_ 259 "VCU to charger. UdcSpnt is the CV regulation target; the termination point in the other charge mode is UdcLim on 0x102 instead. Which of the two carries the knob-selected target is what the dash mode switch chooses.";

VAL_ 519 Flag 0 "None" 1 "Enabled" 2 "Fault" 3 "EnabledFault" ;
VAL_ 521 Flag 0 "None" 1 "Enabled" 2 "Fault" 3 "EnabledFault" ;
VAL_ 523 Flag 0 "None" 1 "Enabled" 2 "Fault" 3 "EnabledFault" ;
VAL_ 2667577584 DiagCode 0 "None" 1 "PecFailure" 2 "BmsFault" 3 "ThreadStartFailure" 4 "InvalidMessage" 5 "SdoAbort" ;
VAL_ 2 InvOpmode 0 "Off" 1 "Run" 2 "ManualRun" 3 "Boost" 4 "Buck" 5 "Sine" 6 "AcHeat" ;
VAL_ 1537 SdoCmd 64 "Read" 67 "ReadReply" 35 "Write" 96 "WriteReply" 128 "Abort" ;
VAL_ 1409 SdoCmd 64 "Read" 67 "ReadReply" 35 "Write" 96 "WriteReply" 128 "Abort" ;
VAL_ 2 InvIo_Ocur 0 "Error" 1 "Ok" 2 "na" ;
VAL_ 2 InvIo_Desat 0 "Error" 1 "Ok" 2 "na" ;

CM_ "914 EV telemetry schema 4.2, SCHEMA_HASH=0x09EB175A. Generated by generate_914_dbc.py -- do not hand-edit.";
